VERSION "stellar_desktop_1.0"

NS_ :

BS_:

BU_: ECU1 Gateway

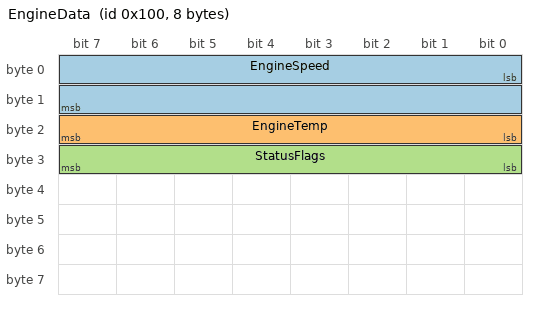
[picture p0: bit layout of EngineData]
BO_ 256 EngineData: 8 ECU1
 SG_ EngineSpeed : 0|16@1+ (0.25,0) [0|8000] "rpm" Gateway
 SG_ EngineTemp : 16|8@1- (1,-40) [-40|215] "degC" Gateway
 SG_ StatusFlags : 24|8@1+ (1,0) [0|255] "" Gateway

CM_ BO_ 256 "Engine data message";
